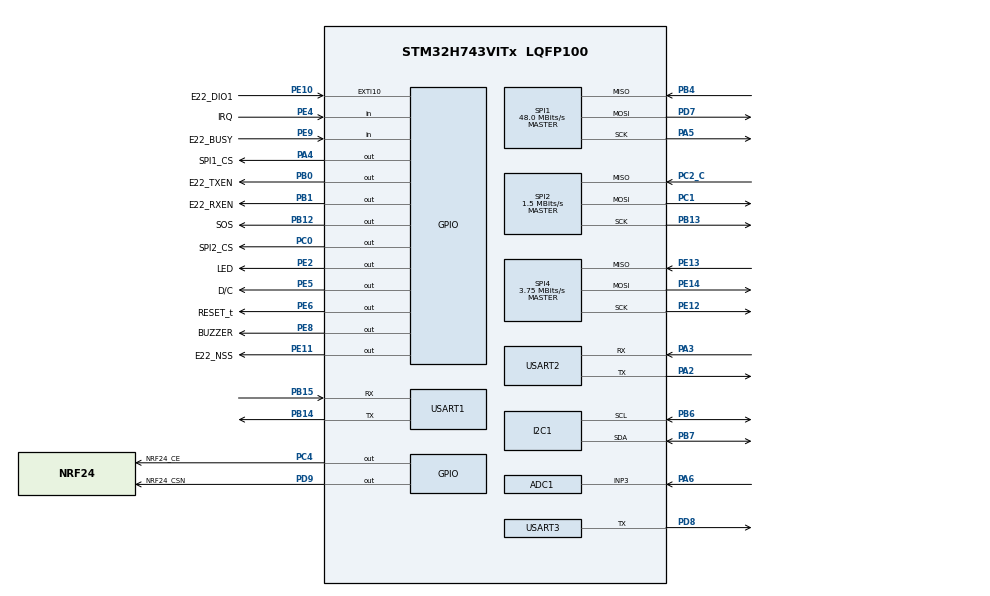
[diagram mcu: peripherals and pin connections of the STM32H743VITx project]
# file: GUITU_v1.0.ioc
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ADC1.Channel-1\#ChannelRegularConversion=ADC_CHANNEL_3
ADC1.ConversionDataManagement=ADC_CONVERSIONDATA_DMA_CIRCULAR
ADC1.NbrOfConversion=1
ADC1.NbrOfConversionFlag=1
ADC1.OffsetNumber-1\#ChannelRegularConversion=ADC_OFFSET_NONE
ADC1.OffsetSignedSaturation-1\#ChannelRegularConversion=DISABLE
ADC1.Rank-1\#ChannelRegularConversion=1
ADC1.SamplingTime-1\#ChannelRegularConversion=ADC_SAMPLETIME_32CYCLES_5
ADC1.master=1
CORTEX_M7.default_mode_Activation=1
Dma.ADC1.4.Direction=DMA_PERIPH_TO_MEMORY
Dma.ADC1.4.EventEnable=DISABLE
Dma.ADC1.4.FIFOMode=DMA_FIFOMODE_DISABLE
Dma.ADC1.4.Instance=DMA1_Stream4
Dma.ADC1.4.MemDataAlignment=DMA_MDATAALIGN_HALFWORD
Dma.ADC1.4.MemInc=DMA_MINC_ENABLE
Dma.ADC1.4.Mode=DMA_NORMAL
Dma.ADC1.4.PeriphDataAlignment=DMA_PDATAALIGN_HALFWORD
Dma.ADC1.4.PeriphInc=DMA_PINC_DISABLE
Dma.ADC1.4.Polarity=HAL_DMAMUX_REQ_GEN_RISING
Dma.ADC1.4.Priority=DMA_PRIORITY_LOW
Dma.ADC1.4.RequestNumber=1
Dma.ADC1.4.SignalID=NONE
Dma.ADC1.4.SyncEnable=DISABLE
Dma.ADC1.4.SyncPolarity=HAL_DMAMUX_SYNC_NO_EVENT
Dma.ADC1.4.SyncRequestNumber=1
Dma.ADC1.4.SyncSignalID=NONE
Dma.Request0=USART1_RX
Dma.Request1=USART1_TX
Dma.Request2=USART2_RX
Dma.Request3=USART2_TX
Dma.Request4=ADC1
Dma.USART1_RX.0.Direction=DMA_PERIPH_TO_MEMORY
Dma.USART1_RX.0.EventEnable=DISABLE
Dma.USART1_RX.0.FIFOMode=DMA_FIFOMODE_DISABLE
Dma.USART1_RX.0.Instance=DMA1_Stream0
Dma.USART1_RX.0.MemDataAlignment=DMA_MDATAALIGN_BYTE
Dma.USART1_RX.0.MemInc=DMA_MINC_ENABLE
Dma.USART1_RX.0.Mode=DMA_NORMAL
Dma.USART1_RX.0.PeriphDataAlignment=DMA_PDATAALIGN_BYTE
Dma.USART1_RX.0.PeriphInc=DMA_PINC_DISABLE
Dma.USART1_RX.0.Polarity=HAL_DMAMUX_REQ_GEN_RISING
Dma.USART1_RX.0.Priority=DMA_PRIORITY_HIGH
Dma.USART1_RX.0.RequestNumber=1
Dma.USART1_RX.0.SignalID=NONE
Dma.USART1_RX.0.SyncEnable=DISABLE
Dma.USART1_RX.0.SyncPolarity=HAL_DMAMUX_SYNC_NO_EVENT
Dma.USART1_RX.0.SyncRequestNumber=1
Dma.USART1_RX.0.SyncSignalID=NONE
Dma.USART1_TX.1.Direction=DMA_MEMORY_TO_PERIPH
Dma.USART1_TX.1.EventEnable=DISABLE
Dma.USART1_TX.1.FIFOMode=DMA_FIFOMODE_DISABLE
Dma.USART1_TX.1.Instance=DMA1_Stream1
Dma.USART1_TX.1.MemDataAlignment=DMA_MDATAALIGN_BYTE
Dma.USART1_TX.1.MemInc=DMA_MINC_ENABLE
Dma.USART1_TX.1.Mode=DMA_NORMAL
Dma.USART1_TX.1.PeriphDataAlignment=DMA_PDATAALIGN_BYTE
Dma.USART1_TX.1.PeriphInc=DMA_PINC_DISABLE
Dma.USART1_TX.1.Polarity=HAL_DMAMUX_REQ_GEN_RISING
Dma.USART1_TX.1.Priority=DMA_PRIORITY_HIGH
Dma.USART1_TX.1.RequestNumber=1
Dma.USART1_TX.1.SignalID=NONE
Dma.USART1_TX.1.SyncEnable=DISABLE
Dma.USART1_TX.1.SyncPolarity=HAL_DMAMUX_SYNC_NO_EVENT
Dma.USART1_TX.1.SyncRequestNumber=1
Dma.USART1_TX.1.SyncSignalID=NONE
Dma.USART2_RX.2.Direction=DMA_PERIPH_TO_MEMORY
Dma.USART2_RX.2.EventEnable=DISABLE
Dma.USART2_RX.2.FIFOMode=DMA_FIFOMODE_DISABLE
Dma.USART2_RX.2.Instance=DMA1_Stream2
Dma.USART2_RX.2.MemDataAlignment=DMA_MDATAALIGN_BYTE
Dma.USART2_RX.2.MemInc=DMA_MINC_ENABLE
Dma.USART2_RX.2.Mode=DMA_NORMAL
Dma.USART2_RX.2.PeriphDataAlignment=DMA_PDATAALIGN_BYTE
Dma.USART2_RX.2.PeriphInc=DMA_PINC_DISABLE
Dma.USART2_RX.2.Polarity=HAL_DMAMUX_REQ_GEN_RISING
Dma.USART2_RX.2.Priority=DMA_PRIORITY_LOW
Dma.USART2_RX.2.RequestNumber=1
Dma.USART2_RX.2.SignalID=NONE
Dma.USART2_RX.2.SyncEnable=DISABLE
Dma.USART2_RX.2.SyncPolarity=HAL_DMAMUX_SYNC_NO_EVENT
Dma.USART2_RX.2.SyncRequestNumber=1
Dma.USART2_RX.2.SyncSignalID=NONE
Dma.USART2_TX.3.Direction=DMA_MEMORY_TO_PERIPH
Dma.USART2_TX.3.EventEnable=DISABLE
Dma.USART2_TX.3.FIFOMode=DMA_FIFOMODE_DISABLE
Dma.USART2_TX.3.Instance=DMA1_Stream3
Dma.USART2_TX.3.MemDataAlignment=DMA_MDATAALIGN_BYTE
Dma.USART2_TX.3.MemInc=DMA_MINC_ENABLE
Dma.USART2_TX.3.Mode=DMA_NORMAL
Dma.USART2_TX.3.PeriphDataAlignment=DMA_PDATAALIGN_BYTE
Dma.USART2_TX.3.PeriphInc=DMA_PINC_DISABLE
Dma.USART2_TX.3.Polarity=HAL_DMAMUX_REQ_GEN_RISING
Dma.USART2_TX.3.Priority=DMA_PRIORITY_LOW
Dma.USART2_TX.3.RequestNumber=1
Dma.USART2_TX.3.SignalID=NONE
Dma.USART2_TX.3.SyncEnable=DISABLE
Dma.USART2_TX.3.SyncPolarity=HAL_DMAMUX_SYNC_NO_EVENT
Dma.USART2_TX.3.SyncRequestNumber=1
Dma.USART2_TX.3.SyncSignalID=NONE
FREERTOS.Tasks01=defaultTask,24,128,StartDefaultTask,Default,NULL,Dynamic,NULL,NULL
FREERTOS.configTOTAL_HEAP_SIZE=131072
I2C1.Timing=0x307075B1
Mcu.Family=STM32H7
Mcu.Name=STM32H743VITx
Mcu.Package=LQFP100
NVIC.ADC_IRQn=true\:5\:0\:false\:false\:true\:true\:true\:true\:true
NVIC.DMA1_Stream0_IRQn=true\:5\:0\:false\:false\:true\:true\:false\:true\:true
NVIC.DMA1_Stream1_IRQn=true\:5\:0\:false\:false\:true\:true\:false\:true\:true
NVIC.DMA1_Stream2_IRQn=true\:5\:0\:false\:false\:true\:true\:false\:true\:true
NVIC.DMA1_Stream3_IRQn=true\:5\:0\:false\:false\:true\:true\:false\:true\:true
NVIC.DMA1_Stream4_IRQn=true\:5\:0\:false\:false\:true\:true\:false\:true\:true
NVIC.EXTI15_10_IRQn=true\:5\:0\:false\:false\:true\:true\:true\:true\:true
NVIC.PriorityGroup=NVIC_PRIORITYGROUP_4
NVIC.TIM17_IRQn=true\:15\:0\:false\:false\:true\:false\:false\:true\:true
NVIC.TimeBase=TIM17_IRQn
NVIC.TimeBaseIP=TIM17
NVIC.USART1_IRQn=true\:5\:0\:false\:false\:true\:true\:false\:true\:true
NVIC.USART2_IRQn=true\:5\:0\:false\:false\:true\:true\:true\:true\:true
PA13\ (JTMS/SWDIO).Mode=Serial_Wire
PA13\ (JTMS/SWDIO).Signal=DEBUG_JTMS-SWDIO
PA14\ (JTCK/SWCLK).Mode=Serial_Wire
PA14\ (JTCK/SWCLK).Signal=DEBUG_JTCK-SWCLK
PA2.Mode=Asynchronous
PA2.Signal=USART2_TX
PA3.Mode=Asynchronous
PA3.Signal=USART2_RX
PA4.GPIO_Label=SPI1_CS
PA4.Signal=GPIO_Output
PA5.GPIO_Speed=GPIO_SPEED_FREQ_VERY_HIGH
PA5.Mode=Full_Duplex_Master
PA5.Signal=SPI1_SCK
PA6.Signal=ADCx_INP3
PB0.GPIO_Label=E22_TXEN
PB0.Signal=GPIO_Output
PB1.GPIO_Label=E22_RXEN
PB1.Signal=GPIO_Output
PB12.GPIO_Label=SOS
PB12.Signal=GPIO_Output
PB13.GPIO_Speed=GPIO_SPEED_FREQ_VERY_HIGH
PB13.Mode=Full_Duplex_Master
PB13.Signal=SPI2_SCK
PB14.Mode=Asynchronous
PB14.Signal=USART1_TX
PB15.Mode=Asynchronous
PB15.Signal=USART1_RX
PB4\ (NJTRST).GPIO_Speed=GPIO_SPEED_FREQ_VERY_HIGH
PB4\ (NJTRST).Mode=Full_Duplex_Master
PB4\ (NJTRST).Signal=SPI1_MISO
PB6.Mode=I2C
PB6.Signal=I2C1_SCL
PB7.Mode=I2C
PB7.Signal=I2C1_SDA
PC0.GPIO_Label=SPI2_CS
PC0.Signal=GPIO_Output
PC1.GPIO_Speed=GPIO_SPEED_FREQ_VERY_HIGH
PC1.Mode=Full_Duplex_Master
PC1.Signal=SPI2_MOSI
PC2_C.GPIO_Speed=GPIO_SPEED_FREQ_VERY_HIGH
PC2_C.Mode=Full_Duplex_Master
PC2_C.Signal=SPI2_MISO
PC4.GPIO_Label=NRF24_CE
PC4.Signal=GPIO_Output
PD7.GPIO_Speed=GPIO_SPEED_FREQ_VERY_HIGH
PD7.Mode=Full_Duplex_Master
PD7.Signal=SPI1_MOSI
PD8.Mode=Asynchronous
PD8.Signal=USART3_TX
PD9.GPIO_Label=NRF24_CSN
PD9.GPIO_OutputLevel=GPIO_PIN_SET
PD9.Signal=GPIO_Output
PE10.GPIO_Label=E22_DIO1
PE10.Signal=GPXTI10
PE11.GPIO_Label=E22_NSS
PE11.GPIO_OutputLevel=GPIO_PIN_SET
PE11.Signal=GPIO_Output
PE12.Mode=Full_Duplex_Master
PE12.Signal=SPI4_SCK
PE13.Mode=Full_Duplex_Master
PE13.Signal=SPI4_MISO
PE14.Mode=Full_Duplex_Master
PE14.Signal=SPI4_MOSI
PE2.GPIO_Label=LED
PE2.Signal=GPIO_Output
PE4.GPIO_Label=IRQ
PE4.Signal=GPIO_Input
PE5.GPIO_Label=D/C
PE5.Signal=GPIO_Output
PE6.GPIO_Label=RESET_t
PE6.Signal=GPIO_Output
PE8.GPIO_Label=BUZZER
PE8.Signal=GPIO_Output
PE9.GPIO_Label=E22_BUSY
PE9.Signal=GPIO_Input
PH0-OSC_IN\ (PH0).Mode=HSE-External-Oscillator
PH0-OSC_IN\ (PH0).Signal=RCC_OSC_IN
PH1-OSC_OUT\ (PH1).Mode=HSE-External-Oscillator
PH1-OSC_OUT\ (PH1).Signal=RCC_OSC_OUT
ProjectManager.HeapSize=0x200
ProjectManager.StackSize=0x400
ProjectManager.TargetToolchain=MDK-ARM V5.32
RCC.ADCFreq_Value=78000000
RCC.APB1Freq_Value=120000000
RCC.APB2Freq_Value=120000000
RCC.APB3Freq_Value=120000000
RCC.APB4Freq_Value=120000000
RCC.CortexFreq_Value=480000000
RCC.D1PPRE=RCC_APB3_DIV2
RCC.D2PPRE1=RCC_APB1_DIV2
RCC.D2PPRE2=RCC_APB2_DIV2
RCC.D3PPRE=RCC_APB4_DIV2
RCC.DIVM1=1
RCC.DIVM2=1
RCC.DIVN1=80
RCC.DIVN2=13
RCC.DIVQ1=5
RCC.HCLKFreq_Value=240000000
RCC.HPRE=RCC_HCLK_DIV2
RCC.HSE_VALUE=12000000
RCC.PLL2FRACN=0
RCC.PLLFRACN=0
RCC.PLLSourceVirtual=RCC_PLLSOURCE_HSE
RCC.SYSCLKFreq_VALUE=480000000
RCC.SYSCLKSource=RCC_SYSCLKSOURCE_PLLCLK
RCC.USBFreq_Value=192000000
SH.ADCx_INP3.0=ADC1_INP3,IN3-Single-Ended
SH.ADCx_INP4.0=ADC1_INP4,IN4-Single-Ended
SPI1.BaudRatePrescaler=SPI_BAUDRATEPRESCALER_4
SPI1.CalculateBaudRate=48.0 MBits/s
SPI1.DataSize=SPI_DATASIZE_8BIT
SPI1.Direction=SPI_DIRECTION_2LINES
SPI1.Mode=SPI_MODE_MASTER
SPI1.VirtualType=VM_MASTER
SPI2.BaudRatePrescaler=SPI_BAUDRATEPRESCALER_128
SPI2.CalculateBaudRate=1.5 MBits/s
SPI2.DataSize=SPI_DATASIZE_8BIT
SPI2.Direction=SPI_DIRECTION_2LINES
SPI2.Mode=SPI_MODE_MASTER
SPI2.VirtualType=VM_MASTER
SPI4.BaudRatePrescaler=SPI_BAUDRATEPRESCALER_32
SPI4.CalculateBaudRate=3.75 MBits/s
SPI4.DataSize=SPI_DATASIZE_8BIT
SPI4.Direction=SPI_DIRECTION_2LINES
SPI4.Mode=SPI_MODE_MASTER
SPI4.VirtualType=VM_MASTER
USART1.VirtualMode-Asynchronous=VM_ASYNC
USART2.VirtualMode-Asynchronous=VM_ASYNC
USART3.VirtualMode-Asynchronous=VM_ASYNC
VP_FREERTOS_VS_CMSIS_V2.Mode=CMSIS_V2
VP_MEMORYMAP_VS_MEMORYMAP.Mode=CurAppReg
VP_SYS_VS_tim17.Mode=TIM17
board=custom

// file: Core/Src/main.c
/* USER CODE BEGIN Header */
/**
  ******************************************************************************
  * @file           : main.c
  * @brief          : Main program body
  ******************************************************************************
  * @attention
  *
  * Copyright (c) 2026 STMicroelectronics.
  * All rights reserved.
  *
  * This software is licensed under terms that can be found in the LICENSE file
  * in the root directory of this software component.
  * If no LICENSE file comes with this software, it is provided AS-IS.
  *
  ******************************************************************************
  */
/* USER CODE END Header */
#include "main.h"
#include "cmsis_os.h"
#include "adc.h"
#include "dma.h"
#include "i2c.h"
#include "spi.h"
#include "usart.h"
#include "gpio.h"

void SystemClock_Config(void);
static void MPU_Config(void);
void MX_FREERTOS_Init(void);

int main(void)
{

  /* MPU Configuration--------------------------------------------------------*/
  MPU_Config();

  /* MCU Configuration--------------------------------------------------------*/

  /* Reset of all peripherals, Initializes the Flash interface and the Systick. */
  HAL_Init();

  /* Configure the system clock */
  SystemClock_Config();

  /* Initialize all configured peripherals */
  MX_GPIO_Init();
  MX_DMA_Init();
  MX_USART1_UART_Init();
  MX_ADC1_Init();
  MX_I2C1_Init();
  MX_SPI1_Init();
  MX_SPI2_Init();
  MX_USART2_UART_Init();
  MX_USART3_UART_Init();
  MX_SPI4_Init();

  /* Init scheduler */
  osKernelInitialize();  /* Call init function for freertos objects (in cmsis_os2.c) */
  MX_FREERTOS_Init();

  /* Start scheduler */
  osKernelStart();

  /* We should never get here as control is now taken by the scheduler */

  /* Infinite loop */
  while (1)
  {

  }
}

void SystemClock_Config(void)
{
  RCC_OscInitTypeDef RCC_OscInitStruct = {0};
  RCC_ClkInitTypeDef RCC_ClkInitStruct = {0};

  /** Supply configuration update enable
  */
  HAL_PWREx_ConfigSupply(PWR_LDO_SUPPLY);

  /** Configure the main internal regulator output voltage
  */
  __HAL_PWR_VOLTAGESCALING_CONFIG(PWR_REGULATOR_VOLTAGE_SCALE0);

  while(!__HAL_PWR_GET_FLAG(PWR_FLAG_VOSRDY)) {}

  /** Initializes the RCC Oscillators according to the specified parameters
  * in the RCC_OscInitTypeDef structure.
  */
  RCC_OscInitStruct.OscillatorType = RCC_OSCILLATORTYPE_HSE;
  RCC_OscInitStruct.HSEState = RCC_HSE_ON;
  RCC_OscInitStruct.PLL.PLLState = RCC_PLL_ON;
  RCC_OscInitStruct.PLL.PLLSource = RCC_PLLSOURCE_HSE;
  RCC_OscInitStruct.PLL.PLLM = 1;
  RCC_OscInitStruct.PLL.PLLN = 80;
  RCC_OscInitStruct.PLL.PLLP = 2;
  RCC_OscInitStruct.PLL.PLLQ = 5;
  RCC_OscInitStruct.PLL.PLLR = 2;
  RCC_OscInitStruct.PLL.PLLRGE = RCC_PLL1VCIRANGE_3;
  RCC_OscInitStruct.PLL.PLLVCOSEL = RCC_PLL1VCOWIDE;
  RCC_OscInitStruct.PLL.PLLFRACN = 0;
  if (HAL_RCC_OscConfig(&RCC_OscInitStruct) != HAL_OK)
  {
    Error_Handler();
  }

  /** Initializes the CPU, AHB and APB buses clocks
  */
  RCC_ClkInitStruct.ClockType = RCC_CLOCKTYPE_HCLK|RCC_CLOCKTYPE_SYSCLK
                              |RCC_CLOCKTYPE_PCLK1|RCC_CLOCKTYPE_PCLK2
                              |RCC_CLOCKTYPE_D3PCLK1|RCC_CLOCKTYPE_D1PCLK1;
  RCC_ClkInitStruct.SYSCLKSource = RCC_SYSCLKSOURCE_PLLCLK;
  RCC_ClkInitStruct.SYSCLKDivider = RCC_SYSCLK_DIV1;
  RCC_ClkInitStruct.AHBCLKDivider = RCC_HCLK_DIV2;
  RCC_ClkInitStruct.APB3CLKDivider = RCC_APB3_DIV2;
  RCC_ClkInitStruct.APB1CLKDivider = RCC_APB1_DIV2;
  RCC_ClkInitStruct.APB2CLKDivider = RCC_APB2_DIV2;
  RCC_ClkInitStruct.APB4CLKDivider = RCC_APB4_DIV2;

  if (HAL_RCC_ClockConfig(&RCC_ClkInitStruct, FLASH_LATENCY_4) != HAL_OK)
  {
    Error_Handler();
  }
}

 /* MPU Configuration */

void MPU_Config(void)
{
  MPU_Region_InitTypeDef MPU_InitStruct = {0};

  /* Disables the MPU */
  HAL_MPU_Disable();

  /** Initializes and configures the Region and the memory to be protected
  */
  MPU_InitStruct.Enable = MPU_REGION_ENABLE;
  MPU_InitStruct.Number = MPU_REGION_NUMBER0;
  MPU_InitStruct.BaseAddress = 0x0;
  MPU_InitStruct.Size = MPU_REGION_SIZE_4GB;
  MPU_InitStruct.SubRegionDisable = 0x87;
  MPU_InitStruct.TypeExtField = MPU_TEX_LEVEL0;
  MPU_InitStruct.AccessPermission = MPU_REGION_NO_ACCESS;
  MPU_InitStruct.DisableExec = MPU_INSTRUCTION_ACCESS_DISABLE;
  MPU_InitStruct.IsShareable = MPU_ACCESS_SHAREABLE;
  MPU_InitStruct.IsCacheable = MPU_ACCESS_NOT_CACHEABLE;
  MPU_InitStruct.IsBufferable = MPU_ACCESS_NOT_BUFFERABLE;

  HAL_MPU_ConfigRegion(&MPU_InitStruct);
  /* Enables the MPU */
  HAL_MPU_Enable(MPU_PRIVILEGED_DEFAULT);

}

void HAL_TIM_PeriodElapsedCallback(TIM_HandleTypeDef *htim)
{
  if (htim->Instance == TIM17)
  {
    HAL_IncTick();
  }
}

void Error_Handler(void)
{
  __disable_irq();
  while (1)
  {
  }
}

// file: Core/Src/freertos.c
/* USER CODE BEGIN Header */
/**
  ******************************************************************************
  * File Name          : freertos.c
  * Description        : Code for freertos applications
  ******************************************************************************
  * @attention
  *
  * Copyright (c) 2026 STMicroelectronics.
  * All rights reserved.
  *
  * This software is licensed under terms that can be found in the LICENSE file
  * in the root directory of this software component.
  * If no LICENSE file comes with this software, it is provided AS-IS.
  *
  ******************************************************************************
  */
/* USER CODE END Header */

#include "FreeRTOS.h"
#include "task.h"
#include "main.h"
#include "cmsis_os.h"

/* USER CODE BEGIN Includes */
#include "app_rtos.h"
/* USER CODE END Includes */

/* Definitions for defaultTask */
osThreadId_t defaultTaskHandle;
const osThreadAttr_t defaultTask_attributes = {
  .name = "defaultTask",
  .stack_size = 128 * 4,
  .priority = (osPriority_t) osPriorityNormal,
};

void StartDefaultTask(void *argument);

void MX_FREERTOS_Init(void); /* (MISRA C 2004 rule 8.1) */

void MX_FREERTOS_Init(void) {

  /* Create the thread(s) */
  /* creation of defaultTask */
  defaultTaskHandle = osThreadNew(StartDefaultTask, NULL, &defaultTask_attributes);

  /* USER CODE BEGIN RTOS_THREADS */
  /* add threads, ... */

  App_RtosCreateObjects();

  /* USER CODE END RTOS_THREADS */

}

void StartDefaultTask(void *argument)
{
  for(;;)
  {
    osDelay(1);
  }
}
